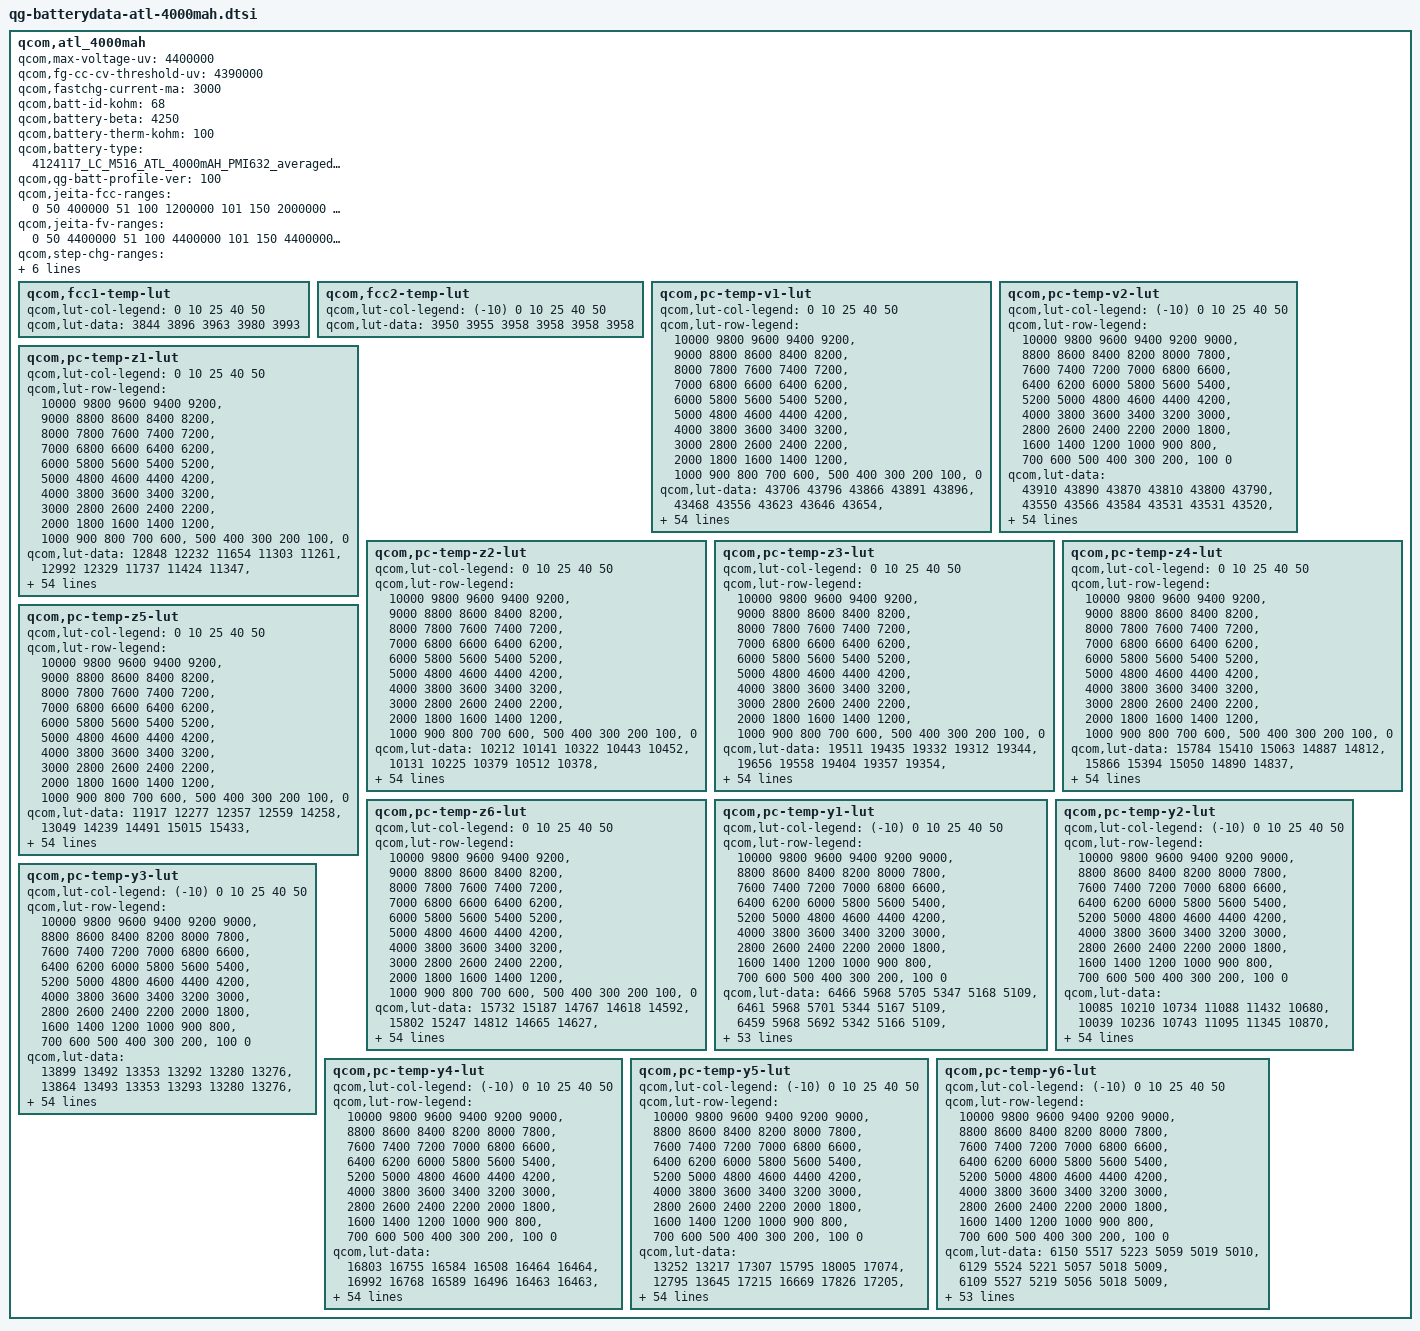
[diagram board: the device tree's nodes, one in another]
// SPDX-License-Identifier: GPL-2.0
/*
 * Copyright (c) 2018-2019, The Linux Foundation. All rights reserved.
 * Copyright (C) 2021 XiaoMi, Inc.
 */

qcom,atl_4000mah {
    /* 4124117_LC_M516_ATL_4000mAH_PMI632_averaged_MasterSlave_Jul25th2019 */
	qcom,max-voltage-uv = <4400000>;
	qcom,fg-cc-cv-threshold-uv = <4390000>;
	qcom,fastchg-current-ma = <3000>;
	qcom,batt-id-kohm = <68>;
    	qcom,battery-beta = <4250>;
	qcom,battery-therm-kohm = <100>;
	qcom,battery-type = "4124117_LC_M516_ATL_4000mAH_PMI632_averaged_MasterSlave_Jul25th2019";
	qcom,qg-batt-profile-ver = <100>;

	qcom,jeita-fcc-ranges = <0   50   400000
                                51   100  1200000
				101  150  2000000
				151  450  3000000
				451  600  2000000>;
	qcom,jeita-fv-ranges = <0    50   4400000
				51   100  4400000
				101  150  4400000
				151  450  4400000
				451  600   4100000>;
	qcom,step-chg-ranges = <3600000  3800000  3450000
				3801000  4300000  2760000
				4301000  4350000  2070000>;

	/* COOL = 5 DegC, WARM = 45 DegC */
	qcom,jeita-soft-thresholds = <0x5316 0x20B9>;
	/* COLD = 0 DegC, HOT = 60 DegC */
	qcom,jeita-hard-thresholds = <0x58CE 0x14A6>;

	qcom,jeita-soft-hys-thresholds = <0x44C4 0x21B5>;
	qcom,jeita-soft-fcc-ua = <2000000 2000000>;
	qcom,jeita-soft-fv-uv = <4400000 4100000>;

	qcom,fcc1-temp-lut {
		qcom,lut-col-legend = <0 10 25 40 50>;
		qcom,lut-data = <3844 3896 3963 3980 3993>;
	};

	qcom,fcc2-temp-lut {
		qcom,lut-col-legend = <(-10) 0 10 25 40 50>;
		qcom,lut-data = <3950 3955 3958 3958 3958 3958>;
	};

	qcom,pc-temp-v1-lut {
		qcom,lut-col-legend = <0 10 25 40 50>;
		qcom,lut-row-legend = <10000 9800 9600 9400 9200>,
			<9000 8800 8600 8400 8200>,
			<8000 7800 7600 7400 7200>,
			<7000 6800 6600 6400 6200>,
			<6000 5800 5600 5400 5200>,
			<5000 4800 4600 4400 4200>,
			<4000 3800 3600 3400 3200>,
			<3000 2800 2600 2400 2200>,
			<2000 1800 1600 1400 1200>,
			<1000 900 800 700 600>,
			<500 400 300 200 100>,
			<0>;
		qcom,lut-data = <43706 43796 43866 43891 43896>,
			<43468 43556 43623 43646 43654>,
			<43220 43315 43381 43406 43416>,
			<42973 43073 43140 43170 43181>,
			<42734 42834 42901 42938 42950>,
			<42501 42599 42663 42706 42720>,
			<42272 42367 42429 42473 42491>,
			<42047 42141 42197 42242 42262>,
			<41827 41920 41971 42014 42036>,
			<41614 41703 41748 41787 41810>,
			<41407 41486 41527 41564 41587>,
			<41209 41274 41308 41345 41366>,
			<41027 41081 41094 41131 41149>,
			<40849 40909 40894 40927 40939>,
			<40638 40727 40701 40729 40735>,
			<40374 40498 40505 40533 40538>,
			<40128 40250 40297 40331 40347>,
			<39957 40053 40101 40136 40164>,
			<39819 39907 39940 39965 39991>,
			<39683 39769 39799 39815 39831>,
			<39551 39616 39634 39651 39662>,
			<39416 39456 39417 39450 39462>,
			<39258 39275 39198 39244 39255>,
			<39076 39032 39015 39060 39071>,
			<38905 38808 38851 38888 38900>,
			<38750 38694 38719 38744 38753>,
			<38611 38624 38620 38630 38634>,
			<38520 38558 38533 38530 38530>,
			<38458 38488 38447 38436 38434>,
			<38408 38420 38365 38346 38342>,
			<38359 38359 38292 38266 38259>,
			<38315 38301 38225 38194 38184>,
			<38274 38248 38166 38129 38115>,
			<38237 38201 38117 38072 38052>,
			<38202 38159 38077 38022 37997>,
			<38169 38121 38035 37973 37940>,
			<38141 38090 37993 37923 37876>,
			<38104 38053 37947 37871 37807>,
			<38043 37990 37882 37803 37728>,
			<37958 37897 37796 37718 37640>,
			<37858 37793 37697 37618 37539>,
			<37734 37673 37581 37500 37419>,
			<37594 37537 37448 37365 37284>,
			<37434 37376 37285 37203 37123>,
			<37296 37236 37146 37069 36995>,
			<37214 37147 37061 36983 36923>,
			<37197 37122 37037 36962 36899>,
			<37171 37107 37024 36944 36883>,
			<37145 37084 37003 36925 36862>,
			<37073 37026 36930 36848 36746>,
			<36778 36755 36625 36547 36408>,
			<36311 36311 36171 36106 35952>,
			<35710 35729 35582 35531 35361>,
			<34887 34946 34775 34757 34551>,
			<33567 33717 33505 33566 33286>,
			<30000 30000 30000 30000 30000>;
	};

	qcom,pc-temp-v2-lut {
		qcom,lut-col-legend = <(-10) 0 10 25 40 50>;
		qcom,lut-row-legend = <10000 9800 9600 9400 9200 9000>,
			<8800 8600 8400 8200 8000 7800>,
			<7600 7400 7200 7000 6800 6600>,
			<6400 6200 6000 5800 5600 5400>,
			<5200 5000 4800 4600 4400 4200>,
			<4000 3800 3600 3400 3200 3000>,
			<2800 2600 2400 2200 2000 1800>,
			<1600 1400 1200 1000 900 800>,
			<700 600 500 400 300 200>,
			<100 0>;
		qcom,lut-data = <43910 43890 43870 43810 43800 43790>,
			<43550 43566 43584 43531 43531 43520>,
			<43219 43265 43311 43265 43271 43260>,
			<42919 42989 43052 43012 43023 43013>,
			<42644 42738 42808 42773 42786 42778>,
			<42393 42495 42569 42539 42553 42547>,
			<42175 42252 42334 42305 42320 42315>,
			<41972 42012 42101 42073 42089 42084>,
			<41743 41781 41873 41845 41862 41857>,
			<41468 41555 41649 41620 41637 41632>,
			<41231 41339 41429 41399 41415 41411>,
			<41092 41142 41218 41182 41197 41194>,
			<40982 40955 41012 40969 40982 40980>,
			<40806 40762 40809 40763 40777 40774>,
			<40474 40565 40605 40563 40580 40573>,
			<40117 40351 40402 40368 40388 40378>,
			<39843 40085 40198 40171 40195 40192>,
			<39598 39788 39993 39976 40005 40014>,
			<39387 39553 39788 39795 39826 39838>,
			<39211 39382 39580 39635 39667 39671>,
			<39048 39225 39376 39468 39501 39498>,
			<38881 39052 39178 39262 39295 39292>,
			<38718 38878 38986 39031 39063 39065>,
			<38572 38726 38819 38841 38871 38876>,
			<38440 38602 38673 38690 38715 38720>,
			<38327 38484 38543 38561 38580 38585>,
			<38240 38350 38427 38446 38464 38468>,
			<38170 38207 38322 38343 38363 38364>,
			<38108 38104 38228 38250 38271 38270>,
			<38052 38036 38142 38163 38185 38182>,
			<38001 37984 38064 38085 38107 38101>,
			<37950 37937 37987 38013 38036 38029>,
			<37902 37896 37914 37946 37971 37965>,
			<37853 37857 37854 37883 37903 37895>,
			<37806 37821 37811 37826 37833 37814>,
			<37757 37783 37772 37770 37757 37726>,
			<37703 37738 37731 37706 37670 37626>,
			<37644 37684 37689 37637 37569 37512>,
			<37575 37620 37638 37563 37474 37408>,
			<37492 37547 37565 37486 37394 37324>,
			<37399 37463 37475 37403 37315 37243>,
			<37302 37360 37370 37303 37218 37145>,
			<37197 37235 37245 37184 37103 37031>,
			<37109 37104 37099 37049 36973 36902>,
			<37033 36977 36962 36926 36859 36792>,
			<36954 36894 36906 36878 36818 36760>,
			<36912 36859 36878 36864 36803 36744>,
			<36858 36826 36857 36843 36789 36725>,
			<36782 36784 36820 36808 36754 36688>,
			<36627 36667 36715 36718 36653 36535>,
			<36344 36367 36413 36409 36313 36154>,
			<35894 35882 35917 35922 35826 35647>,
			<35257 35228 35239 35287 35201 34982>,
			<34347 34304 34344 34447 34349 34095>,
			<32828 32783 32944 33132 33097 32804>,
			<27440 27293 29772 28373 30142 28948>;
	};

	qcom,pc-temp-z1-lut {
		qcom,lut-col-legend = <0 10 25 40 50>;
		qcom,lut-row-legend = <10000 9800 9600 9400 9200>,
			<9000 8800 8600 8400 8200>,
			<8000 7800 7600 7400 7200>,
			<7000 6800 6600 6400 6200>,
			<6000 5800 5600 5400 5200>,
			<5000 4800 4600 4400 4200>,
			<4000 3800 3600 3400 3200>,
			<3000 2800 2600 2400 2200>,
			<2000 1800 1600 1400 1200>,
			<1000 900 800 700 600>,
			<500 400 300 200 100>,
			<0>;
		qcom,lut-data = <12848 12232 11654 11303 11261>,
			<12992 12329 11737 11424 11347>,
			<13025 12345 11779 11498 11406>,
			<13038 12350 11778 11505 11420>,
			<13021 12352 11772 11506 11424>,
			<12977 12353 11766 11506 11428>,
			<12955 12353 11760 11504 11432>,
			<12951 12347 11754 11502 11434>,
			<12949 12323 11751 11501 11435>,
			<12954 12309 11749 11501 11436>,
			<12977 12311 11748 11501 11436>,
			<12991 12315 11747 11501 11436>,
			<12960 12314 11746 11502 11436>,
			<12905 12302 11744 11502 11436>,
			<12880 12290 11740 11502 11436>,
			<12869 12281 11739 11502 11436>,
			<12864 12273 11741 11501 11435>,
			<12869 12271 11743 11500 11435>,
			<12881 12273 11744 11500 11436>,
			<12886 12275 11744 11501 11439>,
			<12876 12274 11745 11501 11441>,
			<12863 12272 11748 11502 11440>,
			<12869 12271 11752 11503 11440>,
			<12900 12275 11755 11504 11440>,
			<12920 12281 11758 11506 11442>,
			<12908 12289 11761 11508 11444>,
			<12888 12300 11765 11512 11446>,
			<12884 12305 11769 11515 11448>,
			<12892 12305 11774 11519 11451>,
			<12899 12304 11780 11522 11453>,
			<12897 12306 11786 11526 11456>,
			<12892 12315 11791 11529 11459>,
			<12891 12324 11795 11532 11463>,
			<12910 12328 11800 11536 11465>,
			<12932 12332 11806 11540 11466>,
			<12932 12336 11811 11544 11468>,
			<12921 12340 11816 11547 11470>,
			<12915 12346 11821 11549 11473>,
			<12939 12354 11824 11552 11475>,
			<12981 12364 11827 11555 11477>,
			<13000 12366 11832 11559 11480>,
			<13006 12360 11841 11561 11483>,
			<13005 12357 11849 11564 11485>,
			<12982 12381 11851 11568 11485>,
			<13004 12400 11861 11572 11488>,
			<13003 12377 11870 11574 11490>,
			<12996 12396 11871 11575 11489>,
			<12970 12390 11869 11575 11490>,
			<12941 12373 11871 11577 11492>,
			<12957 12404 11877 11582 11494>,
			<12998 12417 11874 11585 11499>,
			<12995 12405 11896 11591 11505>,
			<13042 12452 11911 11601 11512>,
			<13070 12483 11915 11616 11524>,
			<13070 12483 11915 11616 11524>,
			<13070 12483 11915 11616 11524>;
	};

	qcom,pc-temp-z2-lut {
		qcom,lut-col-legend = <0 10 25 40 50>;
		qcom,lut-row-legend = <10000 9800 9600 9400 9200>,
			<9000 8800 8600 8400 8200>,
			<8000 7800 7600 7400 7200>,
			<7000 6800 6600 6400 6200>,
			<6000 5800 5600 5400 5200>,
			<5000 4800 4600 4400 4200>,
			<4000 3800 3600 3400 3200>,
			<3000 2800 2600 2400 2200>,
			<2000 1800 1600 1400 1200>,
			<1000 900 800 700 600>,
			<500 400 300 200 100>,
			<0>;
		qcom,lut-data = <10212 10141 10322 10443 10452>,
			<10131 10225 10379 10512 10378>,
			<10132 10227 10408 10547 10349>,
			<10133 10215 10405 10538 10369>,
			<10122 10201 10396 10501 10473>,
			<10092 10186 10386 10473 10535>,
			<10070 10171 10375 10457 10511>,
			<10055 10161 10365 10447 10462>,
			<10045 10151 10360 10447 10399>,
			<10043 10147 10355 10449 10303>,
			<10042 10148 10357 10449 10253>,
			<10042 10150 10385 10399 10274>,
			<10061 10162 10410 10339 10312>,
			<10092 10210 10412 10330 10339>,
			<10097 10245 10412 10329 10364>,
			<10075 10243 10411 10326 10375>,
			<10056 10238 10396 10317 10364>,
			<10068 10239 10382 10307 10348>,
			<10105 10264 10388 10315 10354>,
			<10131 10287 10413 10355 10396>,
			<10144 10288 10444 10400 10435>,
			<10154 10288 10497 10456 10452>,
			<10160 10288 10540 10503 10466>,
			<10164 10292 10521 10499 10495>,
			<10167 10298 10460 10464 10547>,
			<10171 10300 10435 10446 10576>,
			<10174 10300 10473 10555 10561>,
			<10178 10301 10515 10696 10527>,
			<10182 10310 10514 10686 10477>,
			<10187 10322 10496 10565 10390>,
			<10195 10325 10481 10498 10322>,
			<10208 10324 10470 10498 10287>,
			<10222 10324 10463 10499 10264>,
			<10234 10326 10464 10501 10268>,
			<10247 10330 10475 10508 10310>,
			<10259 10336 10489 10514 10364>,
			<10271 10350 10506 10516 10423>,
			<10284 10367 10527 10518 10487>,
			<10301 10384 10555 10526 10537>,
			<10321 10403 10592 10553 10584>,
			<10334 10414 10619 10586 10606>,
			<10342 10419 10637 10627 10574>,
			<10359 10427 10644 10662 10528>,
			<10418 10457 10639 10682 10500>,
			<10718 10630 10689 10604 10495>,
			<10789 10677 10691 10575 10564>,
			<10907 10706 10676 10549 10523>,
			<10966 10784 10693 10642 10517>,
			<10960 10791 10661 10629 10664>,
			<11037 10849 10807 10780 10562>,
			<10963 10936 10904 10511 10296>,
			<10688 11080 10784 10443 10247>,
			<10611 11044 10789 10317 10142>,
			<10328 10905 10712 10283 10139>,
			<10328 10905 10712 10283 10139>,
			<10328 10905 10712 10283 10139>;
	};

	qcom,pc-temp-z3-lut {
		qcom,lut-col-legend = <0 10 25 40 50>;
		qcom,lut-row-legend = <10000 9800 9600 9400 9200>,
			<9000 8800 8600 8400 8200>,
			<8000 7800 7600 7400 7200>,
			<7000 6800 6600 6400 6200>,
			<6000 5800 5600 5400 5200>,
			<5000 4800 4600 4400 4200>,
			<4000 3800 3600 3400 3200>,
			<3000 2800 2600 2400 2200>,
			<2000 1800 1600 1400 1200>,
			<1000 900 800 700 600>,
			<500 400 300 200 100>,
			<0>;
		qcom,lut-data = <19511 19435 19332 19312 19344>,
			<19656 19558 19404 19357 19354>,
			<19732 19602 19449 19388 19365>,
			<19772 19628 19465 19398 19376>,
			<19780 19636 19476 19404 19390>,
			<19783 19637 19477 19407 19396>,
			<19787 19637 19477 19408 19395>,
			<19797 19635 19477 19409 19391>,
			<19805 19625 19471 19408 19386>,
			<19804 19615 19457 19401 19377>,
			<19794 19611 19450 19393 19369>,
			<19778 19607 19448 19384 19366>,
			<19749 19596 19445 19376 19364>,
			<19714 19565 19437 19371 19361>,
			<19710 19544 19424 19368 19359>,
			<19747 19550 19419 19367 19357>,
			<19780 19564 19421 19368 19353>,
			<19766 19566 19422 19369 19347>,
			<19729 19552 19420 19367 19342>,
			<19711 19540 19416 19359 19337>,
			<19707 19543 19415 19354 19334>,
			<19706 19554 19426 19359 19337>,
			<19712 19564 19438 19364 19342>,
			<19740 19575 19434 19361 19341>,
			<19758 19582 19420 19349 19333>,
			<19758 19579 19413 19343 19328>,
			<19757 19565 19411 19352 19342>,
			<19756 19558 19410 19367 19364>,
			<19744 19557 19416 19379 19372>,
			<19730 19557 19435 19392 19375>,
			<19718 19558 19444 19398 19376>,
			<19707 19561 19444 19395 19373>,
			<19697 19562 19444 19389 19366>,
			<19689 19561 19441 19384 19360>,
			<19681 19559 19433 19378 19351>,
			<19673 19555 19427 19372 19347>,
			<19665 19549 19425 19367 19347>,
			<19659 19542 19424 19363 19348>,
			<19655 19538 19421 19358 19347>,
			<19652 19534 19414 19353 19346>,
			<19648 19530 19409 19350 19344>,
			<19640 19526 19405 19354 19348>,
			<19628 19521 19402 19358 19352>,
			<19606 19509 19400 19358 19354>,
			<19526 19470 19390 19351 19351>,
			<19454 19451 19378 19345 19327>,
			<19328 19447 19377 19334 19328>,
			<19321 19419 19358 19334 19324>,
			<19313 19416 19357 19327 19307>,
			<19313 19413 19343 19326 19327>,
			<19325 19395 19336 19349 19347>,
			<19318 19338 19344 19348 19345>,
			<19318 19361 19334 19360 19345>,
			<19320 19326 19342 19358 19349>,
			<19320 19326 19342 19358 19349>,
			<19320 19326 19342 19358 19349>;
	};

	qcom,pc-temp-z4-lut {
		qcom,lut-col-legend = <0 10 25 40 50>;
		qcom,lut-row-legend = <10000 9800 9600 9400 9200>,
			<9000 8800 8600 8400 8200>,
			<8000 7800 7600 7400 7200>,
			<7000 6800 6600 6400 6200>,
			<6000 5800 5600 5400 5200>,
			<5000 4800 4600 4400 4200>,
			<4000 3800 3600 3400 3200>,
			<3000 2800 2600 2400 2200>,
			<2000 1800 1600 1400 1200>,
			<1000 900 800 700 600>,
			<500 400 300 200 100>,
			<0>;
		qcom,lut-data = <15784 15410 15063 14887 14812>,
			<15866 15394 15050 14890 14837>,
			<15706 15330 15026 14891 14848>,
			<15512 15193 14983 14882 14843>,
			<15385 15080 14924 14850 14816>,
			<15275 15005 14878 14821 14789>,
			<15182 14945 14843 14798 14771>,
			<15099 14901 14815 14778 14758>,
			<15033 14867 14793 14762 14749>,
			<14990 14840 14774 14750 14744>,
			<14959 14815 14760 14742 14738>,
			<14938 14795 14746 14740 14732>,
			<14927 14787 14738 14737 14725>,
			<14919 14782 14738 14732 14718>,
			<14902 14780 14737 14723 14709>,
			<14860 14778 14736 14714 14703>,
			<14825 14777 14729 14705 14699>,
			<14820 14774 14718 14698 14696>,
			<14818 14757 14705 14693 14692>,
			<14814 14740 14690 14689 14689>,
			<14796 14733 14687 14687 14687>,
			<14776 14729 14715 14709 14706>,
			<14775 14730 14756 14746 14743>,
			<14782 14792 14793 14780 14774>,
			<14791 14861 14832 14818 14804>,
			<14815 14865 14845 14835 14818>,
			<14844 14849 14835 14815 14796>,
			<14850 14832 14816 14782 14757>,
			<14840 14815 14793 14755 14732>,
			<14826 14796 14760 14728 14715>,
			<14815 14779 14737 14710 14703>,
			<14803 14761 14724 14700 14695>,
			<14793 14748 14715 14694 14689>,
			<14783 14740 14709 14692 14686>,
			<14774 14734 14704 14691 14685>,
			<14766 14730 14703 14691 14685>,
			<14759 14726 14703 14694 14688>,
			<14753 14724 14703 14699 14694>,
			<14748 14726 14707 14706 14698>,
			<14744 14733 14718 14714 14702>,
			<14742 14735 14724 14718 14704>,
			<14742 14728 14716 14706 14694>,
			<14741 14722 14709 14696 14685>,
			<14738 14720 14708 14696 14686>,
			<14722 14703 14695 14689 14678>,
			<14771 14692 14682 14677 14676>,
			<14904 14690 14673 14676 14663>,
			<14907 14710 14679 14656 14648>,
			<14909 14705 14669 14646 14644>,
			<14906 14706 14688 14650 14632>,
			<14900 14741 14718 14655 14644>,
			<14923 14810 14712 14659 14648>,
			<14929 14787 14725 14650 14650>,
			<14937 14832 14719 14653 14647>,
			<14937 14832 14719 14653 14647>,
			<14937 14832 14719 14653 14647>;
	};

	qcom,pc-temp-z5-lut {
		qcom,lut-col-legend = <0 10 25 40 50>;
		qcom,lut-row-legend = <10000 9800 9600 9400 9200>,
			<9000 8800 8600 8400 8200>,
			<8000 7800 7600 7400 7200>,
			<7000 6800 6600 6400 6200>,
			<6000 5800 5600 5400 5200>,
			<5000 4800 4600 4400 4200>,
			<4000 3800 3600 3400 3200>,
			<3000 2800 2600 2400 2200>,
			<2000 1800 1600 1400 1200>,
			<1000 900 800 700 600>,
			<500 400 300 200 100>,
			<0>;
		qcom,lut-data = <11917 12277 12357 12559 14258>,
			<13049 14239 14491 15015 15433>,
			<13862 15392 16030 16704 16552>,
			<14443 16205 16903 17353 17696>,
			<14763 16895 17528 17705 18957>,
			<14975 17569 18093 18048 19539>,
			<15277 18110 18656 18460 19506>,
			<15921 18395 19053 18821 19425>,
			<16542 18552 19205 19072 19225>,
			<16725 18765 19298 19278 18703>,
			<16808 19396 19531 19334 18404>,
			<16839 20115 20351 18867 18537>,
			<16349 20068 21018 18324 18828>,
			<15535 18944 20514 18334 19238>,
			<15814 18104 19296 18642 19929>,
			<19835 19000 18916 19114 20297>,
			<23372 20772 19565 20301 20158>,
			<22618 21359 20640 21695 19954>,
			<20345 21387 21868 22390 19979>,
			<19408 21418 23594 22804 20321>,
			<20250 23582 26239 23291 20723>,
			<22051 29533 32674 24193 21177>,
			<26767 33877 38181 24984 21582>,
			<38478 36615 35583 23817 20946>,
			<45441 38342 26757 19094 17531>,
			<44867 36503 21528 16595 15385>,
			<43422 29397 19658 16846 16043>,
			<41361 25271 18647 17423 17435>,
			<37278 24868 19284 18684 18963>,
			<33326 24656 21974 21699 20933>,
			<31170 25004 24887 24609 22691>,
			<29543 27117 28382 26970 24052>,
			<28809 29415 31179 28929 25143>,
			<28571 31250 31495 29999 25701>,
			<28418 32821 31508 30756 25992>,
			<28251 33097 31548 31041 26324>,
			<28077 32388 32321 30122 27046>,
			<27995 31635 33276 28252 27788>,
			<29254 31366 32399 25960 27357>,
			<31332 31200 28243 22614 24405>,
			<31715 30889 25094 20900 22485>,
			<30339 30080 24014 21689 23608>,
			<28843 28877 23211 22425 24742>,
			<27463 26872 22308 21893 24531>,
			<25715 26054 22632 20831 23742>,
			<21109 24810 22007 20218 18000>,
			<12459 24084 22424 18351 18792>,
			<12313 18434 18427 20280 20117>,
			<12196 18331 18897 20731 18103>,
			<12236 18285 16345 19297 24726>,
			<12513 16037 14539 19869 23300>,
			<12177 13036 14759 18534 21328>,
			<12093 13638 13934 21150 19811>,
			<11959 12430 14101 19461 19731>,
			<11959 12430 14101 19461 19731>,
			<11959 12430 14101 19461 19731>;
	};

	qcom,pc-temp-z6-lut {
		qcom,lut-col-legend = <0 10 25 40 50>;
		qcom,lut-row-legend = <10000 9800 9600 9400 9200>,
			<9000 8800 8600 8400 8200>,
			<8000 7800 7600 7400 7200>,
			<7000 6800 6600 6400 6200>,
			<6000 5800 5600 5400 5200>,
			<5000 4800 4600 4400 4200>,
			<4000 3800 3600 3400 3200>,
			<3000 2800 2600 2400 2200>,
			<2000 1800 1600 1400 1200>,
			<1000 900 800 700 600>,
			<500 400 300 200 100>,
			<0>;
		qcom,lut-data = <15732 15187 14767 14618 14592>,
			<15802 15247 14812 14665 14627>,
			<15737 15232 14832 14691 14648>,
			<15652 15174 14823 14691 14650>,
			<15582 15120 14800 14682 14647>,
			<15512 15080 14781 14673 14642>,
			<15455 15045 14766 14665 14636>,
			<15412 15014 14751 14657 14629>,
			<15377 14988 14736 14648 14621>,
			<15346 14966 14721 14639 14614>,
			<15320 14952 14711 14632 14608>,
			<15294 14939 14704 14626 14603>,
			<15263 14923 14699 14620 14598>,
			<15232 14900 14693 14614 14594>,
			<15216 14887 14686 14608 14589>,
			<15208 14888 14681 14603 14584>,
			<15201 14891 14678 14601 14579>,
			<15188 14890 14675 14598 14575>,
			<15171 14876 14669 14594 14571>,
			<15159 14863 14660 14587 14566>,
			<15151 14863 14658 14585 14564>,
			<15145 14867 14677 14597 14574>,
			<15148 14875 14701 14615 14592>,
			<15166 14909 14714 14628 14604>,
			<15185 14944 14725 14639 14614>,
			<15199 14944 14728 14643 14619>,
			<15212 14932 14723 14640 14616>,
			<15213 14922 14716 14635 14612>,
			<15205 14915 14711 14631 14607>,
			<15194 14909 14707 14627 14603>,
			<15184 14904 14703 14622 14598>,
			<15175 14900 14700 14617 14592>,
			<15167 14896 14696 14613 14587>,
			<15160 14893 14692 14608 14582>,
			<15155 14890 14686 14604 14577>,
			<15150 14888 14684 14602 14575>,
			<15146 14886 14684 14601 14576>,
			<15144 14885 14684 14601 14579>,
			<15145 14886 14684 14601 14580>,
			<15147 14890 14686 14602 14581>,
			<15148 14892 14688 14602 14581>,
			<15149 14890 14684 14600 14579>,
			<15149 14888 14680 14598 14578>,
			<15144 14886 14680 14599 14579>,
			<15111 14868 14672 14592 14574>,
			<15095 14855 14661 14584 14562>,
			<15089 14852 14656 14578 14557>,
			<15087 14847 14649 14570 14548>,
			<15086 14845 14645 14562 14537>,
			<15090 14847 14647 14563 14542>,
			<15100 14857 14659 14579 14560>,
			<15115 14863 14663 14583 14563>,
			<15128 14873 14667 14586 14566>,
			<15152 14885 14673 14590 14570>,
			<15152 14885 14673 14590 14570>,
			<15152 14885 14673 14590 14570>;
	};

	qcom,pc-temp-y1-lut {
		qcom,lut-col-legend = <(-10) 0 10 25 40 50>;
		qcom,lut-row-legend = <10000 9800 9600 9400 9200 9000>,
			<8800 8600 8400 8200 8000 7800>,
			<7600 7400 7200 7000 6800 6600>,
			<6400 6200 6000 5800 5600 5400>,
			<5200 5000 4800 4600 4400 4200>,
			<4000 3800 3600 3400 3200 3000>,
			<2800 2600 2400 2200 2000 1800>,
			<1600 1400 1200 1000 900 800>,
			<700 600 500 400 300 200>,
			<100 0>;
		qcom,lut-data = <6466 5968 5705 5347 5168 5109>,
			<6461 5968 5701 5344 5167 5109>,
			<6459 5968 5692 5342 5166 5109>,
			<6457 5968 5682 5339 5164 5109>,
			<6457 5968 5673 5335 5163 5109>,
			<6456 5968 5669 5332 5161 5109>,
			<6457 5968 5669 5327 5158 5108>,
			<6459 5966 5669 5323 5156 5106>,
			<6459 5965 5668 5320 5153 5105>,
			<6454 5963 5665 5318 5150 5104>,
			<6451 5962 5661 5317 5148 5103>,
			<6457 5969 5657 5313 5148 5101>,
			<6471 5982 5651 5309 5149 5099>,
			<6472 5985 5645 5307 5149 5099>,
			<6443 5976 5635 5306 5146 5100>,
			<6417 5967 5629 5305 5144 5101>,
			<6428 5973 5634 5305 5145 5101>,
			<6455 5985 5646 5305 5147 5100>,
			<6470 5988 5652 5305 5148 5099>,
			<6477 5980 5655 5306 5147 5100>,
			<6481 5972 5656 5307 5146 5100>,
			<6476 5981 5655 5310 5146 5101>,
			<6461 6003 5652 5315 5146 5102>,
			<6454 6010 5651 5319 5147 5103>,
			<6451 5989 5658 5323 5150 5103>,
			<6450 5967 5665 5326 5154 5103>,
			<6454 5966 5665 5329 5154 5104>,
			<6464 5966 5663 5332 5154 5107>,
			<6467 5968 5663 5335 5154 5110>,
			<6432 5978 5665 5339 5157 5112>,
			<6391 5989 5667 5344 5162 5114>,
			<6388 5985 5670 5351 5166 5116>,
			<6398 5968 5673 5359 5170 5119>,
			<6407 5960 5676 5363 5173 5121>,
			<6414 5971 5680 5363 5175 5123>,
			<6419 5985 5683 5364 5177 5125>,
			<6419 5985 5685 5365 5178 5126>,
			<6415 5981 5686 5369 5179 5126>,
			<6413 5979 5688 5374 5181 5127>,
			<6418 5983 5690 5378 5183 5128>,
			<6426 5989 5693 5383 5186 5129>,
			<6418 5988 5697 5388 5187 5131>,
			<6378 5981 5700 5392 5188 5133>,
			<6381 5979 5703 5397 5191 5135>,
			<6422 5980 5705 5403 5196 5137>,
			<6406 5982 5712 5407 5199 5140>,
			<6386 5995 5722 5408 5196 5141>,
			<6433 5986 5691 5415 5196 5139>,
			<6432 6015 5729 5414 5195 5139>,
			<6438 6017 5722 5412 5198 5141>,
			<6400 5984 5723 5412 5199 5140>,
			<6397 6004 5709 5425 5206 5146>,
			<6417 6029 5752 5430 5212 5153>,
			<6456 6039 5753 5459 5219 5159>,
			<6456 6039 5753 5459 5219 5159>,
			<6456 6039 5753 5459 5219 5159>;
	};

	qcom,pc-temp-y2-lut {
		qcom,lut-col-legend = <(-10) 0 10 25 40 50>;
		qcom,lut-row-legend = <10000 9800 9600 9400 9200 9000>,
			<8800 8600 8400 8200 8000 7800>,
			<7600 7400 7200 7000 6800 6600>,
			<6400 6200 6000 5800 5600 5400>,
			<5200 5000 4800 4600 4400 4200>,
			<4000 3800 3600 3400 3200 3000>,
			<2800 2600 2400 2200 2000 1800>,
			<1600 1400 1200 1000 900 800>,
			<700 600 500 400 300 200>,
			<100 0>;
		qcom,lut-data = <10085 10210 10734 11088 11432 10680>,
			<10039 10236 10743 11095 11345 10870>,
			<10021 10262 10746 11091 11233 10988>,
			<10024 10286 10745 11080 11119 11052>,
			<10042 10307 10741 11062 11022 11078>,
			<10067 10322 10734 11040 10966 11083>,
			<10103 10333 10722 11003 10942 11039>,
			<10156 10341 10708 10964 10928 10959>,
			<10239 10344 10706 10958 10930 10933>,
			<10408 10345 10713 10979 10969 10928>,
			<10523 10347 10718 11001 11008 10923>,
			<10502 10461 10718 11010 11029 10917>,
			<10454 10680 10718 11017 11044 10912>,
			<10451 10740 10727 11027 11052 10915>,
			<10569 10708 10814 11041 11054 10963>,
			<10706 10681 10902 11061 11058 11025>,
			<10787 10693 10934 11095 11090 11073>,
			<10851 10729 10955 11147 11166 11121>,
			<10827 10773 10972 11204 11250 11175>,
			<10278 10832 10983 11279 11366 11252>,
			<9739 10898 10996 11331 11447 11304>,
			<9696 10970 11017 11304 11391 11290>,
			<9690 11044 11044 11234 11247 11244>,
			<9685 11063 11068 11209 11196 11200>,
			<9681 11009 11087 11225 11206 11151>,
			<9678 10954 11105 11250 11222 11118>,
			<9676 10950 11131 11272 11242 11128>,
			<9674 10952 11160 11296 11271 11170>,
			<9673 10954 11171 11320 11308 11218>,
			<9671 10960 11172 11347 11377 11283>,
			<9669 10965 11172 11367 11434 11339>,
			<9668 10949 11174 11371 11439 11354>,
			<9667 10888 11178 11372 11438 11360>,
			<9667 10833 11180 11372 11436 11366>,
			<9666 10803 11170 11372 11434 11374>,
			<9665 10767 11153 11371 11431 11380>,
			<9664 10575 11130 11359 11416 11369>,
			<9663 10032 11097 11322 11369 11324>,
			<9663 9726 11070 11296 11320 11285>,
			<9662 9698 11054 11288 11266 11258>,
			<9662 9683 11038 11281 11224 11239>,
			<9662 9676 11010 11253 11218 11244>,
			<9661 9672 10954 11196 11217 11266>,
			<9660 9669 10664 11192 11234 11209>,
			<9660 9666 10206 11201 11266 11009>,
			<9659 9663 10693 11085 11071 10885>,
			<9659 9664 10688 11118 11107 10880>,
			<9659 9662 10654 11113 11077 10934>,
			<9658 9661 10628 11065 11031 10954>,
			<9658 9660 10624 11055 11073 10871>,
			<9657 9658 10574 11073 11030 10882>,
			<9657 9657 10454 10976 10899 10819>,
			<9655 9656 9968 10932 10904 10739>,
			<9654 9655 9788 10884 10873 10699>,
			<9654 9655 9788 10884 10873 10699>,
			<9654 9655 9788 10884 10873 10699>;
	};

	qcom,pc-temp-y3-lut {
		qcom,lut-col-legend = <(-10) 0 10 25 40 50>;
		qcom,lut-row-legend = <10000 9800 9600 9400 9200 9000>,
			<8800 8600 8400 8200 8000 7800>,
			<7600 7400 7200 7000 6800 6600>,
			<6400 6200 6000 5800 5600 5400>,
			<5200 5000 4800 4600 4400 4200>,
			<4000 3800 3600 3400 3200 3000>,
			<2800 2600 2400 2200 2000 1800>,
			<1600 1400 1200 1000 900 800>,
			<700 600 500 400 300 200>,
			<100 0>;
		qcom,lut-data = <13899 13492 13353 13292 13280 13276>,
			<13864 13493 13353 13293 13280 13276>,
			<13822 13493 13354 13295 13280 13276>,
			<13781 13493 13354 13296 13281 13277>,
			<13750 13493 13354 13297 13281 13278>,
			<13736 13492 13355 13298 13282 13279>,
			<13741 13488 13356 13299 13283 13280>,
			<13751 13481 13357 13299 13284 13281>,
			<13744 13481 13357 13299 13285 13282>,
			<13675 13496 13358 13300 13286 13283>,
			<13600 13507 13358 13301 13287 13284>,
			<13556 13484 13359 13301 13287 13285>,
			<13521 13438 13360 13301 13287 13285>,
			<13514 13426 13360 13302 13288 13286>,
			<13520 13434 13356 13305 13293 13287>,
			<13526 13441 13352 13308 13296 13287>,
			<13503 13437 13352 13307 13294 13288>,
			<13448 13426 13353 13304 13291 13290>,
			<13429 13415 13353 13304 13289 13291>,
			<13431 13405 13350 13305 13291 13289>,
			<13435 13395 13345 13307 13292 13287>,
			<13438 13382 13340 13305 13289 13284>,
			<13442 13369 13335 13299 13284 13281>,
			<13442 13362 13331 13297 13281 13279>,
			<13425 13359 13328 13296 13280 13277>,
			<13407 13356 13325 13296 13279 13276>,
			<13406 13350 13322 13295 13280 13276>,
			<13411 13342 13319 13293 13280 13276>,
			<13419 13336 13318 13293 13281 13276>,
			<13436 13333 13319 13293 13280 13276>,
			<13460 13331 13320 13293 13280 13276>,
			<13480 13332 13319 13293 13280 13276>,
			<13500 13336 13316 13293 13280 13276>,
			<13521 13341 13315 13293 13281 13277>,
			<13546 13346 13316 13293 13281 13277>,
			<13573 13351 13318 13294 13282 13278>,
			<13600 13358 13320 13294 13281 13277>,
			<13627 13370 13323 13293 13279 13276>,
			<13655 13381 13325 13292 13278 13276>,
			<13686 13391 13325 13291 13278 13277>,
			<13719 13401 13325 13290 13280 13278>,
			<13752 13416 13325 13291 13281 13279>,
			<13787 13438 13326 13291 13281 13280>,
			<13830 13472 13322 13292 13282 13279>,
			<13885 13523 13315 13295 13282 13277>,
			<13939 13572 13333 13296 13286 13284>,
			<13882 13536 13329 13297 13286 13285>,
			<13916 13590 13336 13300 13293 13287>,
			<13978 13651 13344 13306 13293 13289>,
			<14030 13706 13351 13311 13293 13286>,
			<14110 13773 13355 13307 13287 13284>,
			<14205 13880 13361 13307 13288 13286>,
			<14351 14026 13360 13310 13294 13288>,
			<14644 14176 13408 13323 13299 13296>,
			<14644 14176 13408 13323 13299 13296>,
			<14644 14176 13408 13323 13299 13296>;
	};

	qcom,pc-temp-y4-lut {
		qcom,lut-col-legend = <(-10) 0 10 25 40 50>;
		qcom,lut-row-legend = <10000 9800 9600 9400 9200 9000>,
			<8800 8600 8400 8200 8000 7800>,
			<7600 7400 7200 7000 6800 6600>,
			<6400 6200 6000 5800 5600 5400>,
			<5200 5000 4800 4600 4400 4200>,
			<4000 3800 3600 3400 3200 3000>,
			<2800 2600 2400 2200 2000 1800>,
			<1600 1400 1200 1000 900 800>,
			<700 600 500 400 300 200>,
			<100 0>;
		qcom,lut-data = <16803 16755 16584 16508 16464 16464>,
			<16992 16768 16589 16496 16463 16463>,
			<17107 16785 16593 16489 16463 16461>,
			<17167 16803 16596 16485 16463 16459>,
			<17190 16818 16597 16483 16463 16458>,
			<17193 16827 16598 16483 16463 16457>,
			<17148 16830 16597 16484 16464 16457>,
			<17066 16832 16595 16489 16464 16457>,
			<17051 16828 16595 16493 16465 16457>,
			<17102 16796 16601 16498 16468 16458>,
			<17176 16771 16608 16503 16472 16461>,
			<17284 16842 16613 16509 16477 16464>,
			<17410 16983 16620 16517 16483 16467>,
			<17420 17022 16636 16526 16487 16471>,
			<17185 17006 16692 16537 16489 16476>,
			<16959 16976 16734 16550 16492 16482>,
			<16914 16903 16733 16568 16501 16487>,
			<16891 16788 16723 16587 16519 16494>,
			<16884 16744 16707 16597 16535 16503>,
			<16882 16739 16666 16603 16555 16524>,
			<16881 16735 16621 16606 16568 16540>,
			<16853 16720 16588 16585 16553 16529>,
			<16779 16695 16560 16528 16513 16499>,
			<16741 16673 16544 16496 16488 16480>,
			<16731 16655 16536 16481 16473 16470>,
			<16725 16636 16531 16474 16465 16464>,
			<16728 16606 16531 16474 16465 16464>,
			<16737 16566 16533 16478 16467 16467>,
			<16741 16551 16534 16483 16471 16470>,
			<16734 16558 16530 16489 16478 16476>,
			<16726 16568 16524 16494 16487 16483>,
			<16726 16574 16521 16500 16496 16492>,
			<16728 16578 16517 16506 16507 16503>,
			<16730 16583 16516 16509 16511 16507>,
			<16731 16589 16523 16508 16508 16503>,
			<16732 16597 16533 16508 16503 16497>,
			<16736 16615 16542 16505 16493 16486>,
			<16743 16650 16552 16496 16474 16468>,
			<16746 16673 16556 16491 16465 16459>,
			<16741 16679 16557 16491 16467 16461>,
			<16733 16683 16558 16492 16470 16463>,
			<16731 16683 16558 16494 16471 16464>,
			<16730 16682 16559 16498 16471 16464>,
			<16733 16674 16570 16493 16465 16459>,
			<16750 16661 16591 16483 16453 16448>,
			<16776 16677 16566 16496 16463 16457>,
			<16755 16675 16562 16494 16470 16473>,
			<16769 16694 16580 16505 16485 16502>,
			<16791 16716 16602 16525 16516 16527>,
			<16802 16741 16618 16542 16522 16509>,
			<16793 16734 16605 16503 16467 16459>,
			<16777 16724 16602 16499 16465 16460>,
			<16786 16734 16652 16516 16473 16465>,
			<16870 16779 16708 16558 16496 16507>,
			<16870 16779 16708 16558 16496 16507>,
			<16870 16779 16708 16558 16496 16507>;
	};

	qcom,pc-temp-y5-lut {
		qcom,lut-col-legend = <(-10) 0 10 25 40 50>;
		qcom,lut-row-legend = <10000 9800 9600 9400 9200 9000>,
			<8800 8600 8400 8200 8000 7800>,
			<7600 7400 7200 7000 6800 6600>,
			<6400 6200 6000 5800 5600 5400>,
			<5200 5000 4800 4600 4400 4200>,
			<4000 3800 3600 3400 3200 3000>,
			<2800 2600 2400 2200 2000 1800>,
			<1600 1400 1200 1000 900 800>,
			<700 600 500 400 300 200>,
			<100 0>;
		qcom,lut-data = <13252 13217 17307 15795 18005 17074>,
			<12795 13645 17215 16669 17826 17205>,
			<12582 14134 17143 17203 17647 17456>,
			<12574 14597 17090 17480 17479 17745>,
			<12732 14947 17057 17585 17334 17990>,
			<13019 15094 17046 17601 17225 18107>,
			<14404 15021 17066 17264 17162 18120>,
			<16514 14894 17101 16571 17110 18126>,
			<16740 15020 17061 16086 16993 18100>,
			<14522 16154 16680 15761 16691 17876>,
			<12755 17038 16207 15439 16306 17557>,
			<13162 15859 15782 15008 15799 17198>,
			<14432 13520 15373 14568 15259 16757>,
			<16284 13253 15182 14370 15184 16293>,
			<20277 16959 15085 14275 15693 15709>,
			<23287 20138 15040 14231 16120 15344>,
			<21651 19760 16383 14311 15596 15420>,
			<17486 18703 19465 14585 14448 15604>,
			<15543 18375 21074 15169 14149 15645>,
			<15007 18621 21772 17504 14970 15464>,
			<14748 18851 22122 19882 16088 15298>,
			<14862 18845 22005 20803 17117 16021>,
			<15191 18802 21591 21404 18151 17773>,
			<15272 18923 21073 21692 18463 18400>,
			<14178 21136 20243 21849 18445 18271>,
			<12857 23400 19456 21930 18408 18037>,
			<12402 22229 19054 21395 18305 17654>,
			<12134 18298 18763 19904 18068 17023>,
			<12057 15955 18764 19141 17781 16436>,
			<12258 15113 20531 18960 17327 15826>,
			<12561 14655 22425 18868 16960 15401>,
			<12746 14772 21886 18989 16992 15435>,
			<12879 15364 19772 19452 17251 15713>,
			<13051 16007 18812 19958 17655 16135>,
			<13386 16773 18872 20584 18855 17250>,
			<13738 17395 18997 21084 20043 18448>,
			<13904 17040 19269 20919 19838 18863>,
			<14010 15416 19812 20038 18655 19091>,
			<14051 14442 20063 19073 17931 19160>,
			<14014 14340 19662 18052 17771 18801>,
			<13922 14273 18973 17117 17681 18347>,
			<13694 14110 18443 16627 17646 18790>,
			<13150 13850 17940 16325 17629 20437>,
			<13051 13903 16209 16737 18008 19555>,
			<13166 14151 13925 17676 18800 17082>,
			<13247 13839 16910 16360 17317 18430>,
			<13512 13383 15928 16832 16907 17245>,
			<13674 13546 16202 16469 18876 16649>,
			<14122 14095 16516 17228 17395 16685>,
			<14030 14119 17301 18485 17417 15772>,
			<14167 13826 18086 19632 17873 18985>,
			<14044 13968 18082 20127 18089 19226>,
			<13865 14222 14443 19496 21816 19744>,
			<13600 13941 15052 23340 25271 27014>,
			<13600 13941 15052 23340 25271 27014>,
			<13600 13941 15052 23340 25271 27014>;
	};

	qcom,pc-temp-y6-lut {
		qcom,lut-col-legend = <(-10) 0 10 25 40 50>;
		qcom,lut-row-legend = <10000 9800 9600 9400 9200 9000>,
			<8800 8600 8400 8200 8000 7800>,
			<7600 7400 7200 7000 6800 6600>,
			<6400 6200 6000 5800 5600 5400>,
			<5200 5000 4800 4600 4400 4200>,
			<4000 3800 3600 3400 3200 3000>,
			<2800 2600 2400 2200 2000 1800>,
			<1600 1400 1200 1000 900 800>,
			<700 600 500 400 300 200>,
			<100 0>;
		qcom,lut-data = <6150 5517 5223 5059 5019 5010>,
			<6129 5524 5221 5057 5018 5009>,
			<6109 5527 5219 5056 5018 5009>,
			<6090 5527 5217 5056 5018 5009>,
			<6073 5525 5214 5055 5018 5009>,
			<6057 5522 5212 5055 5019 5010>,
			<6044 5517 5208 5056 5019 5010>,
			<6031 5509 5205 5057 5020 5011>,
			<6013 5503 5203 5058 5021 5012>,
			<5979 5497 5202 5059 5023 5013>,
			<5958 5494 5202 5061 5024 5014>,
			<5964 5498 5202 5063 5026 5016>,
			<5977 5504 5203 5065 5027 5017>,
			<5977 5506 5205 5068 5030 5019>,
			<5932 5506 5216 5073 5033 5021>,
			<5879 5506 5225 5078 5036 5023>,
			<5850 5490 5224 5082 5038 5025>,
			<5828 5454 5223 5086 5040 5028>,
			<5814 5435 5219 5089 5044 5031>,
			<5806 5429 5205 5092 5050 5036>,
			<5799 5423 5188 5093 5054 5039>,
			<5790 5413 5175 5086 5048 5034>,
			<5781 5402 5164 5066 5033 5022>,
			<5777 5398 5158 5055 5023 5015>,
			<5778 5397 5154 5051 5018 5011>,
			<5778 5397 5152 5048 5015 5008>,
			<5784 5394 5152 5049 5016 5008>,
			<5800 5386 5152 5050 5017 5009>,
			<5819 5383 5153 5051 5018 5010>,
			<5836 5393 5155 5053 5020 5012>,
			<5855 5409 5157 5055 5023 5014>,
			<5874 5426 5159 5057 5026 5017>,
			<5892 5445 5159 5060 5030 5020>,
			<5912 5465 5161 5062 5031 5022>,
			<5935 5487 5167 5063 5031 5021>,
			<5960 5510 5176 5064 5030 5020>,
			<5985 5533 5185 5063 5027 5017>,
			<6011 5556 5194 5060 5020 5011>,
			<6037 5582 5203 5059 5017 5009>,
			<6064 5612 5210 5059 5018 5010>,
			<6091 5645 5218 5060 5020 5011>,
			<6119 5682 5227 5062 5021 5012>,
			<6149 5723 5239 5064 5022 5014>,
			<6189 5772 5253 5065 5021 5012>,
			<6240 5829 5270 5066 5018 5008>,
			<6296 5891 5297 5073 5025 5016>,
			<6254 5861 5282 5072 5027 5021>,
			<6289 5918 5306 5078 5036 5031>,
			<6346 5980 5332 5088 5045 5040>,
			<6398 6043 5359 5097 5047 5032>,
			<6464 6105 5375 5083 5027 5017>,
			<6549 6206 5412 5086 5028 5019>,
			<6685 6339 5471 5097 5035 5023>,
			<6988 6489 5577 5125 5047 5042>,
			<6988 6489 5577 5125 5047 5042>,
			<6988 6489 5577 5125 5047 5042>;
	};
};
